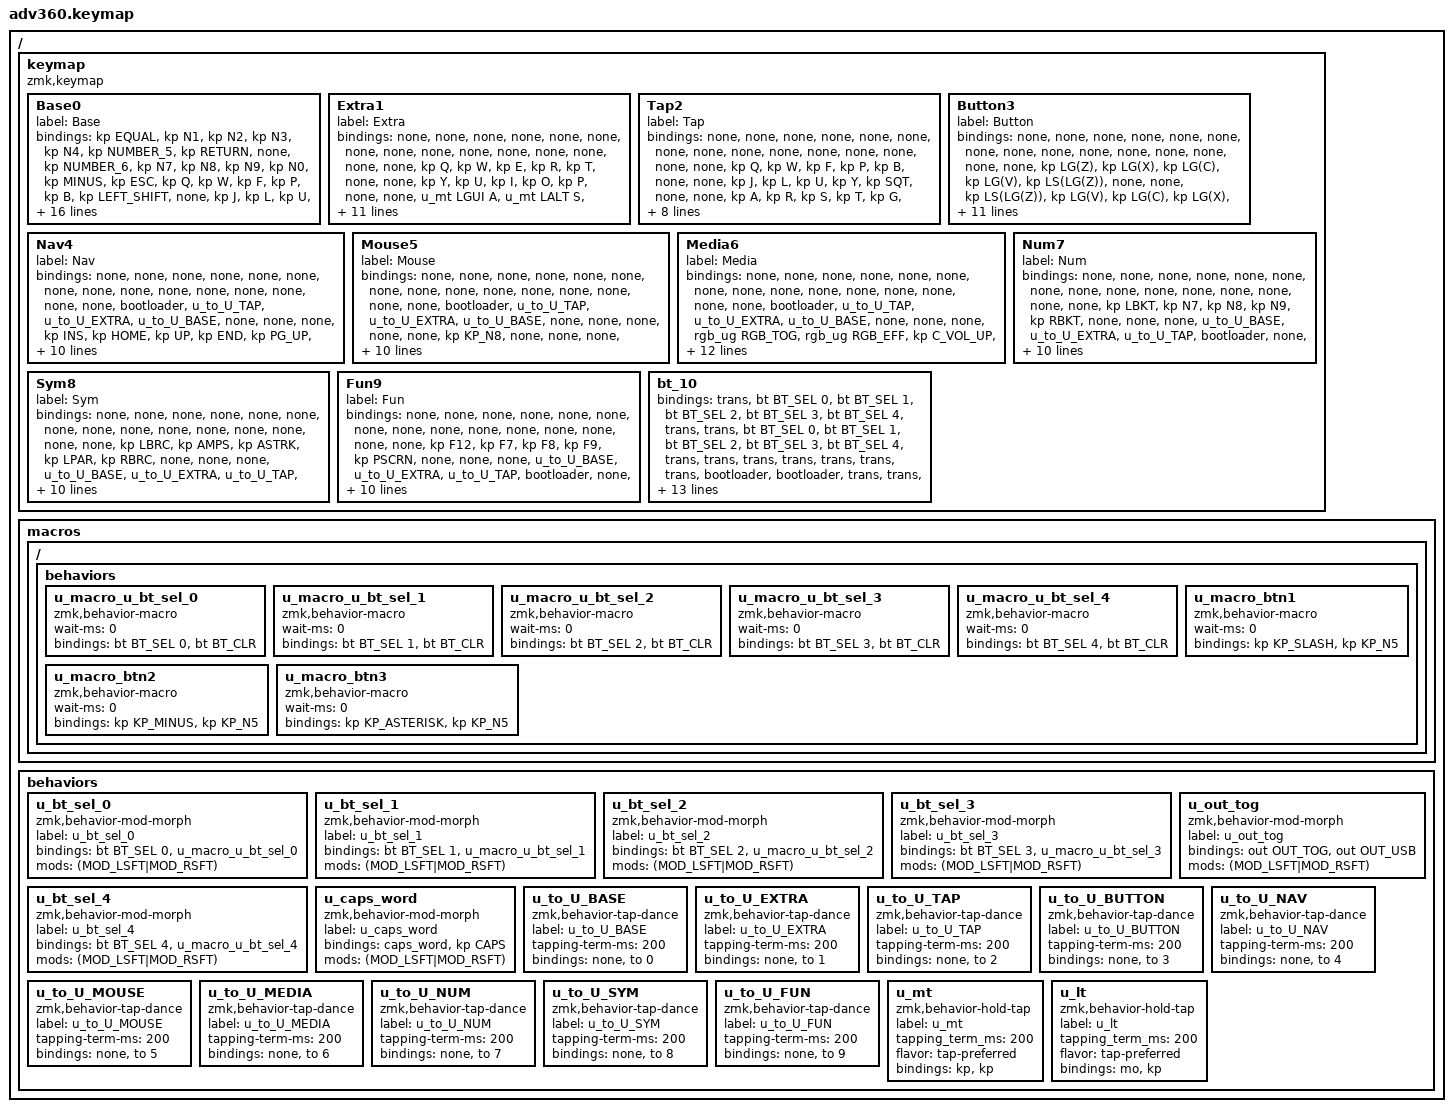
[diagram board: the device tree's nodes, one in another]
#include <behaviors.dtsi>
#include <dt-bindings/zmk/backlight.h>
#include <dt-bindings/zmk/bt.h>
#include <dt-bindings/zmk/ext_power.h>
#include <dt-bindings/zmk/keys.h>
#include <dt-bindings/zmk/outputs.h>
#include <dt-bindings/zmk/rgb.h>

/ {
    keymap {
        compatible = "zmk,keymap";

        Base0 {
            label = "Base";
            bindings = <
     &kp EQUAL                &kp N1            &kp N2             &kp N3         &kp N4  &kp NUMBER_5      &kp RETURN                 &none           &kp NUMBER_6          &kp N7         &kp N8        &kp N9        &kp N0      &kp MINUS
       &kp ESC                 &kp Q             &kp W              &kp F          &kp P         &kp B  &kp LEFT_SHIFT                 &none                  &kp J           &kp L          &kp U         &kp Y      &kp SEMI  &kp BACKSLASH
       &kp TAB  &u_mt LEFT_CONTROL A      &u_mt LALT R       &u_mt LGUI S  &u_mt LSHFT T         &kp G         &kp TAB              &kp LGUI               &kp LALT                                     &kp RALT         &none          &none      &kp M  &u_mt RSHFT N  &u_mt RGUI E    &u_mt RALT I  &u_mt RCTRL O          &kp SQT
&kp LEFT_SHIFT             &u_lt 3 Z      &u_mt RALT X              &kp C          &kp D         &kp V           &none                 &none              &kp GRAVE           &none          &none  &kp CAPSLOCK         &none          &none      &kp K          &kp H     &kp COMMA  &u_mt RALT DOT  &u_lt 3 SLASH  &kp RIGHT_SHIFT
         &none            &kp RETURN  &kp LEFT_BRACKET  &kp RIGHT_BRACKET        &kp DEL  &u_lt 6 BSPC   &u_lt 4 SPACE  &u_lt 5 LEFT_CONTROL  &u_lt 8 RIGHT_CONTROL  &u_lt 7 RETURN  &u_lt 9 SPACE      &kp LEFT  &kp UP_ARROW       &kp DOWN  &kp RIGHT          &none
            >;
        };

        Extra1 {
            label = "Extra";
            bindings = <
&none         &none         &none          &none          &none        &none          &none        &none        &none         &none        &none  &none  &none  &none
&none         &kp Q         &kp W          &kp E          &kp R        &kp T          &none        &none        &kp Y         &kp U        &kp I  &kp O  &kp P  &none
&none  &u_mt LGUI A  &u_mt LALT S  &u_mt LCTRL D  &u_mt LSHFT F        &kp G          &none        &none        &none                             &none  &none  &none  &kp H  &u_mt LSHFT J  &u_mt LCTRL K    &u_mt LALT L  &u_mt LGUI SQT  &none
&none     &u_lt 3 Z  &u_mt RALT X          &kp C          &kp V        &kp B          &none        &none        &none         &none        &none  &none  &none  &none  &kp N          &kp M      &kp COMMA  &u_mt RALT DOT   &u_lt 3 SLASH  &none
&none         &none         &none          &none          &none  &u_lt 6 ESC  &u_lt 4 SPACE  &u_lt 5 TAB  &u_lt 8 RET  &u_lt 7 BSPC  &u_lt 9 DEL  &none  &none  &none  &none          &none
            >;
        };

        Tap2 {
            label = "Tap";
            bindings = <
&none  &none  &none  &none  &none    &none      &none    &none    &none     &none    &none  &none    &none  &none
&none  &kp Q  &kp W  &kp F  &kp P    &kp B      &none    &none    &kp J     &kp L    &kp U  &kp Y  &kp SQT  &none
&none  &kp A  &kp R  &kp S  &kp T    &kp G      &none    &none    &none                     &none    &none  &none  &kp M  &kp N      &kp E    &kp I      &kp O  &none
&none  &kp Z  &kp X  &kp C  &kp D    &kp V      &none    &none    &none     &none    &none  &none    &none  &none  &kp K  &kp H  &kp COMMA  &kp DOT  &kp SLASH  &none
&none  &none  &none  &none  &none  &kp ESC  &kp SPACE  &kp TAB  &kp RET  &kp BSPC  &kp DEL  &none    &none  &none  &none  &none
            >;
        };

        Button3 {
            label = "Button";
            bindings = <
&none      &none      &none      &none      &none          &none          &none          &none          &none          &none          &none      &none      &none  &none
&none  &kp LG(Z)  &kp LG(X)  &kp LG(C)  &kp LG(V)  &kp LS(LG(Z))          &none          &none  &kp LS(LG(Z))      &kp LG(V)      &kp LG(C)  &kp LG(X)  &kp LG(Z)  &none
&none   &kp LGUI   &kp LALT  &kp LCTRL  &kp LSHFT          &none          &none          &none          &none                                    &none      &none  &none          &none  &kp LSHFT  &kp LCTRL   &kp LALT   &kp LGUI  &none
&none  &kp LG(Z)  &kp LG(X)  &kp LG(C)  &kp LG(V)  &kp LS(LG(Z))          &none          &none          &none          &none          &none      &none      &none  &none  &kp LS(LG(Z))  &kp LG(V)  &kp LG(C)  &kp LG(X)  &kp LG(Z)  &none
&none      &none      &none      &none      &none  &u_macro_btn3  &u_macro_btn1  &u_macro_btn2  &u_macro_btn2  &u_macro_btn1  &u_macro_btn3      &none      &none  &none          &none      &none
            >;
        };

        Nav4 {
            label = "Nav";
            bindings = <
&none        &none        &none          &none         &none  &none  &none  &none    &none     &none    &none    &none      &none  &none
&none  &bootloader  &u_to_U_TAP  &u_to_U_EXTRA  &u_to_U_BASE  &none  &none  &none  &kp INS  &kp HOME   &kp UP  &kp END  &kp PG_UP  &none
&none     &kp LGUI     &kp LALT      &kp LCTRL     &kp LSHFT  &none  &none  &none    &none                       &none      &none  &none   &u_caps_word   &kp LEFT   &kp DOWN  &kp RIGHT  &kp PG_DN  &none
&none        &none     &kp RALT    &u_to_U_NUM   &u_to_U_NAV  &none  &none  &none    &none     &none    &none    &none      &none  &none  &kp LS(LG(Z))  &kp LG(V)  &kp LG(C)  &kp LG(X)  &kp LG(Z)  &none
&none        &none        &none          &none         &none  &none  &none  &none  &kp RET  &kp BSPC  &kp DEL    &none      &none  &none          &none      &none
            >;
        };

        Mouse5 {
            label = "Mouse";
            bindings = <
&none        &none        &none          &none          &none  &none  &none  &none          &none          &none          &none  &none  &none  &none
&none  &bootloader  &u_to_U_TAP  &u_to_U_EXTRA   &u_to_U_BASE  &none  &none  &none          &none          &none      &kp KP_N8  &none  &none  &none
&none     &kp LGUI     &kp LALT      &kp LCTRL      &kp LSHFT  &none  &none  &none          &none                                &none  &none  &none          &none  &kp KP_N4  &kp KP_N2  &kp KP_N6      &none  &none
&none        &none     &kp RALT    &u_to_U_SYM  &u_to_U_MOUSE  &none  &none  &none          &none          &none          &none  &none  &none  &none  &kp LS(LG(Z))  &kp LG(V)  &kp LG(C)  &kp LG(X)  &kp LG(Z)  &none
&none        &none        &none          &none          &none  &none  &none  &none  &u_macro_btn2  &u_macro_btn1  &u_macro_btn3  &none  &none  &none          &none      &none
            >;
        };

        Media6 {
            label = "Media";
            bindings = <
&none        &none        &none          &none          &none  &none  &none  &none            &none            &none         &none            &none            &none  &none
&none  &bootloader  &u_to_U_TAP  &u_to_U_EXTRA   &u_to_U_BASE  &none  &none  &none  &rgb_ug RGB_TOG  &rgb_ug RGB_EFF  &kp C_VOL_UP  &rgb_ug RGB_HUI  &rgb_ug RGB_SAI  &none
&none     &kp LGUI     &kp LALT      &kp LCTRL      &kp LSHFT  &none  &none  &none            &none                                           &none            &none  &none  &ext_power EP_TOG   &kp C_PREV  &kp C_VOL_DN   &kp C_NEXT  &rgb_ug RGB_BRI  &none
&none        &none     &kp RALT    &u_to_U_FUN  &u_to_U_MEDIA  &none  &none  &none            &none            &none         &none            &none            &none  &none         &u_out_tog  &u_bt_sel_0   &u_bt_sel_1  &u_bt_sel_2      &u_bt_sel_3  &none
&none        &none        &none          &none          &none  &none  &none  &none       &kp C_STOP         &kp C_PP    &kp C_MUTE            &none            &none  &none              &none        &none
            >;
        };

        Num7 {
            label = "Num";
            bindings = <
&none      &none   &none   &none   &none      &none   &none      &none  &none         &none          &none        &none        &none  &none
&none   &kp LBKT  &kp N7  &kp N8  &kp N9   &kp RBKT   &none      &none  &none  &u_to_U_BASE  &u_to_U_EXTRA  &u_to_U_TAP  &bootloader  &none
&none   &kp SEMI  &kp N4  &kp N5  &kp N6  &kp EQUAL   &none      &none  &none                                     &none        &none  &none  &none    &kp LSHFT    &kp LCTRL  &kp LALT  &kp LGUI  &none
&none  &kp GRAVE  &kp N1  &kp N2  &kp N3   &kp BSLH   &none      &none  &none         &none          &none        &none        &none  &none  &none  &u_to_U_NUM  &u_to_U_NAV  &kp RALT     &none  &none
&none      &none   &none   &none   &none    &kp DOT  &kp N0  &kp MINUS  &none         &none          &none        &none        &none  &none  &none        &none
            >;
        };

        Sym8 {
            label = "Sym";
            bindings = <
&none      &none     &none      &none      &none     &none     &none      &none  &none         &none          &none        &none        &none  &none
&none   &kp LBRC  &kp AMPS  &kp ASTRK   &kp LPAR  &kp RBRC     &none      &none  &none  &u_to_U_BASE  &u_to_U_EXTRA  &u_to_U_TAP  &bootloader  &none
&none  &kp COLON  &kp DLLR  &kp PRCNT  &kp CARET  &kp PLUS     &none      &none  &none                                     &none        &none  &none  &none    &kp LSHFT      &kp LCTRL  &kp LALT  &kp LGUI  &none
&none  &kp TILDE  &kp EXCL     &kp AT   &kp HASH  &kp PIPE     &none      &none  &none         &none          &none        &none        &none  &none  &none  &u_to_U_SYM  &u_to_U_MOUSE  &kp RALT     &none  &none
&none      &none     &none      &none      &none  &kp LPAR  &kp RPAR  &kp UNDER  &none         &none          &none        &none        &none  &none  &none        &none
            >;
        };

        Fun9 {
            label = "Fun";
            bindings = <
&none    &none   &none   &none   &none            &none      &none    &none  &none         &none          &none        &none        &none  &none
&none  &kp F12  &kp F7  &kp F8  &kp F9        &kp PSCRN      &none    &none  &none  &u_to_U_BASE  &u_to_U_EXTRA  &u_to_U_TAP  &bootloader  &none
&none  &kp F11  &kp F4  &kp F5  &kp F6         &kp SLCK      &none    &none  &none                                     &none        &none  &none  &none    &kp LSHFT      &kp LCTRL  &kp LALT  &kp LGUI  &none
&none  &kp F10  &kp F1  &kp F2  &kp F3  &kp PAUSE_BREAK      &none    &none  &none         &none          &none        &none        &none  &none  &none  &u_to_U_FUN  &u_to_U_MEDIA  &kp RALT     &none  &none
&none    &none   &none   &none   &none        &kp K_APP  &kp SPACE  &kp TAB  &none         &none          &none        &none        &none  &none  &none        &none
            >;
        };

        bt_10 {
            bindings = <
&trans  &bt BT_SEL 0  &bt BT_SEL 1  &bt BT_SEL 2  &bt BT_SEL 3     &bt BT_SEL 4       &trans       &trans  &bt BT_SEL 0  &bt BT_SEL 1     &bt BT_SEL 2  &bt BT_SEL 3  &bt BT_SEL 4  &trans
&trans        &trans        &trans        &trans        &trans           &trans  &bootloader  &bootloader        &trans        &trans           &trans        &trans        &trans  &trans
&trans        &trans        &trans        &trans        &trans           &trans      &rgb_ug RGB_MEFS_CMD 5  &rgb_ug RGB_MEFS_CMD 5         &none                                   &bt BT_CLR    &bt BT_CLR  &trans  &trans  &trans  &trans  &trans  &trans  &trans
&trans        &trans        &trans        &trans        &trans           &trans       &trans       &trans         &none        &trans           &trans         &none        &trans  &trans  &trans  &trans  &trans  &trans  &trans  &trans
&trans        &trans        &trans    &bl BL_INC    &bl BL_DEC  &rgb_ug RGB_TOG   &bl BL_TOG        &none         &none    &bl BL_TOG  &rgb_ug RGB_TOG    &bl BL_INC    &bl BL_DEC  &trans  &trans  &mo 10
            >;
        };
    };
};

/ {
    macros {
        ZMK_MACRO(u_macro_u_bt_sel_0,

        wait-ms = <0>;
        bindings = <&bt BT_SEL 0 &bt BT_CLR>;

        )
    };
};

/ {
    behaviors {
        u_bt_sel_0: u_bt_sel_0 {
            compatible = "zmk,behavior-mod-morph";
            label = "u_bt_sel_0";
            #binding-cells = <0>;
            bindings =
                <&bt BT_SEL 0>,
                <&u_macro_u_bt_sel_0>;

            mods = <(MOD_LSFT|MOD_RSFT)>;
        };
    };
};

/ {
    macros {
        ZMK_MACRO(u_macro_u_bt_sel_1,

        wait-ms = <0>;
        bindings = <&bt BT_SEL 1 &bt BT_CLR>;

        )
    };
};

/ {
    behaviors {
        u_bt_sel_1: u_bt_sel_1 {
            compatible = "zmk,behavior-mod-morph";
            label = "u_bt_sel_1";
            #binding-cells = <0>;
            bindings =
                <&bt BT_SEL 1>,
                <&u_macro_u_bt_sel_1>;

            mods = <(MOD_LSFT|MOD_RSFT)>;
        };
    };
};

/ {
    macros {
        ZMK_MACRO(u_macro_u_bt_sel_2,

        wait-ms = <0>;
        bindings = <&bt BT_SEL 2 &bt BT_CLR>;

        )
    };
};

/ {
    behaviors {
        u_bt_sel_2: u_bt_sel_2 {
            compatible = "zmk,behavior-mod-morph";
            label = "u_bt_sel_2";
            #binding-cells = <0>;
            bindings =
                <&bt BT_SEL 2>,
                <&u_macro_u_bt_sel_2>;

            mods = <(MOD_LSFT|MOD_RSFT)>;
        };
    };
};

/ {
    macros {
        ZMK_MACRO(u_macro_u_bt_sel_3,

        wait-ms = <0>;
        bindings = <&bt BT_SEL 3 &bt BT_CLR>;

        )
    };
};

/ {
    behaviors {
        u_bt_sel_3: u_bt_sel_3 {
            compatible = "zmk,behavior-mod-morph";
            label = "u_bt_sel_3";
            #binding-cells = <0>;
            bindings =
                <&bt BT_SEL 3>,
                <&u_macro_u_bt_sel_3>;

            mods = <(MOD_LSFT|MOD_RSFT)>;
        };
    };
};

/ {
    macros {
        ZMK_MACRO(u_macro_u_bt_sel_4,

        wait-ms = <0>;
        bindings = <&bt BT_SEL 4 &bt BT_CLR>;

        )
    };
};

/ {
    behaviors {
        u_bt_sel_4: u_bt_sel_4 {
            compatible = "zmk,behavior-mod-morph";
            label = "u_bt_sel_4";
            #binding-cells = <0>;
            bindings =
                <&bt BT_SEL 4>,
                <&u_macro_u_bt_sel_4>;

            mods = <(MOD_LSFT|MOD_RSFT)>;
        };
    };
};

/ {
    behaviors {
        u_out_tog: u_out_tog {
            compatible = "zmk,behavior-mod-morph";
            label = "u_out_tog";
            #binding-cells = <0>;
            bindings =
                <&out OUT_TOG>,
                <&out OUT_USB>;

            mods = <(MOD_LSFT|MOD_RSFT)>;
        };
    };
};

/ {
    behaviors {
        u_caps_word: u_caps_word {
            compatible = "zmk,behavior-mod-morph";
            label = "u_caps_word";
            #binding-cells = <0>;
            bindings =
                <&caps_word>,
                <&kp CAPS>;

            mods = <(MOD_LSFT|MOD_RSFT)>;
        };
    };
};

/ {
    behaviors {
        u_to_U_BASE: u_to_U_BASE {
            compatible = "zmk,behavior-tap-dance";
            label = "u_to_U_BASE";
            #binding-cells = <0>;
            tapping-term-ms = <200>;
            bindings =
                <&none>,
                <&to 0>;
        };
    };
};

/ {
    behaviors {
        u_to_U_EXTRA: u_to_U_EXTRA {
            compatible = "zmk,behavior-tap-dance";
            label = "u_to_U_EXTRA";
            #binding-cells = <0>;
            tapping-term-ms = <200>;
            bindings =
                <&none>,
                <&to 1>;
        };
    };
};

/ {
    behaviors {
        u_to_U_TAP: u_to_U_TAP {
            compatible = "zmk,behavior-tap-dance";
            label = "u_to_U_TAP";
            #binding-cells = <0>;
            tapping-term-ms = <200>;
            bindings =
                <&none>,
                <&to 2>;
        };
    };
};

/ {
    behaviors {
        u_to_U_BUTTON: u_to_U_BUTTON {
            compatible = "zmk,behavior-tap-dance";
            label = "u_to_U_BUTTON";
            #binding-cells = <0>;
            tapping-term-ms = <200>;
            bindings =
                <&none>,
                <&to 3>;
        };
    };
};

/ {
    behaviors {
        u_to_U_NAV: u_to_U_NAV {
            compatible = "zmk,behavior-tap-dance";
            label = "u_to_U_NAV";
            #binding-cells = <0>;
            tapping-term-ms = <200>;
            bindings =
                <&none>,
                <&to 4>;
        };
    };
};

/ {
    behaviors {
        u_to_U_MOUSE: u_to_U_MOUSE {
            compatible = "zmk,behavior-tap-dance";
            label = "u_to_U_MOUSE";
            #binding-cells = <0>;
            tapping-term-ms = <200>;
            bindings =
                <&none>,
                <&to 5>;
        };
    };
};

/ {
    behaviors {
        u_to_U_MEDIA: u_to_U_MEDIA {
            compatible = "zmk,behavior-tap-dance";
            label = "u_to_U_MEDIA";
            #binding-cells = <0>;
            tapping-term-ms = <200>;
            bindings =
                <&none>,
                <&to 6>;
        };
    };
};

/ {
    behaviors {
        u_to_U_NUM: u_to_U_NUM {
            compatible = "zmk,behavior-tap-dance";
            label = "u_to_U_NUM";
            #binding-cells = <0>;
            tapping-term-ms = <200>;
            bindings =
                <&none>,
                <&to 7>;
        };
    };
};

/ {
    behaviors {
        u_to_U_SYM: u_to_U_SYM {
            compatible = "zmk,behavior-tap-dance";
            label = "u_to_U_SYM";
            #binding-cells = <0>;
            tapping-term-ms = <200>;
            bindings =
                <&none>,
                <&to 8>;
        };
    };
};

/ {
    behaviors {
        u_to_U_FUN: u_to_U_FUN {
            compatible = "zmk,behavior-tap-dance";
            label = "u_to_U_FUN";
            #binding-cells = <0>;
            tapping-term-ms = <200>;
            bindings =
                <&none>,
                <&to 9>;
        };
    };
};

/ {
    macros {
        ZMK_MACRO(u_macro_btn1, wait-ms = <0>; bindings = <&kp KP_SLASH &kp KP_N5>;)
    ZMK_MACRO(u_macro_btn2, wait-ms = <0>; bindings = <&kp KP_MINUS &kp KP_N5>;)
    ZMK_MACRO(u_macro_btn3,

        wait-ms = <0>;
        bindings = <&kp KP_ASTERISK &kp KP_N5>;

        )
    };
};

/ {
    behaviors {
        u_mt: u_mt {
            compatible = "zmk,behavior-hold-tap";
            label = "u_mt";
            #binding-cells = <2>;
            tapping_term_ms = <200>;
            flavor = "tap-preferred";
            bindings =
                <&kp>,
                <&kp>;
        };
        u_lt: u_lt {
            compatible = "zmk,behavior-hold-tap";
            label = "u_lt";
            #binding-cells = <2>;
            tapping_term_ms = <200>;
            flavor = "tap-preferred";
            bindings =
                <&mo>,
                <&kp>;
        };
    };
};
